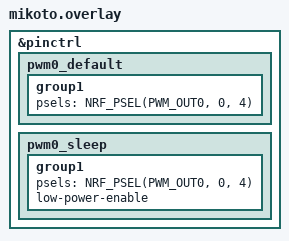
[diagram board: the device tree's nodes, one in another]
&pinctrl {
    pwm0_default: pwm0_default {
        group1 {
            // Use P0.08 for LED backlight
            psels = <NRF_PSEL(PWM_OUT0, 0, 4)>;
          };
    };

    pwm0_sleep: pwm0_sleep {
        group1 {
            // Use P0.08 for LED backlight
            psels = <NRF_PSEL(PWM_OUT0, 0, 4)>;
            low-power-enable;
          };
    };
};
